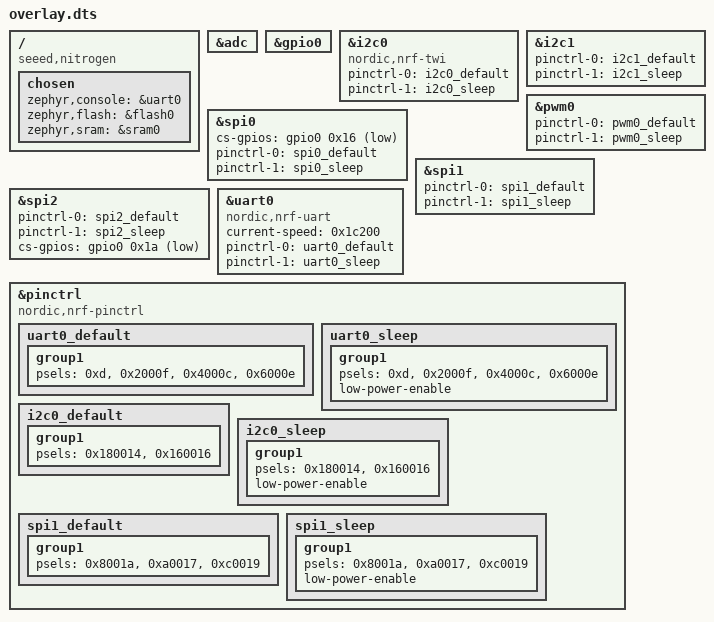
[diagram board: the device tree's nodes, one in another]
/ {
	compatible = "seeed,nitrogen";
	chosen {
		zephyr,console = &uart0;
		zephyr,flash = &flash0;
		zephyr,sram = &sram0;
	};
};
&adc{
	status = "okay";
};
&gpio0{
	status = "okay";
};
&i2c0{
	compatible = "nordic,nrf-twi";
	status = "okay";
	pinctrl-0 = < &i2c0_default >;
	pinctrl-1 = < &i2c0_sleep >;
	pinctrl-names = "default", "sleep";
};
&i2c1{
	status = "okay";
	pinctrl-0 = < &i2c1_default >;
	pinctrl-1 = < &i2c1_sleep >;
	pinctrl-names = "default", "sleep";
};
&pwm0{
	status = "okay";
	pinctrl-0 = < &pwm0_default >;
	pinctrl-1 = < &pwm0_sleep >;
	pinctrl-names = "default", "sleep";
};
&spi0{
	cs-gpios = < &gpio0 0x16 0x1 >;
	pinctrl-0 = < &spi0_default >;
	pinctrl-1 = < &spi0_sleep >;
	pinctrl-names = "default", "sleep";
};
&spi1{
	status = "okay";
	pinctrl-0 = < &spi1_default >;
	pinctrl-1 = < &spi1_sleep >;
	pinctrl-names = "default", "sleep";
};
&spi2{
	status = "okay";
	pinctrl-0 = < &spi2_default >;
	pinctrl-1 = < &spi2_sleep >;
	pinctrl-names = "default", "sleep";
	cs-gpios = < &gpio0 0x1a 0x1 >;
};
&uart0{
	compatible = "nordic,nrf-uart";
	status = "okay";
	current-speed = < 0x1c200 >;
	pinctrl-0 = < &uart0_default >;
	pinctrl-1 = < &uart0_sleep >;
	pinctrl-names = "default", "sleep";
};
&pinctrl{
	compatible = "nordic,nrf-pinctrl";
	uart0_default: uart0_default {
		group1 {
			psels = < 0xd >, < 0x2000f >, < 0x4000c >, < 0x6000e >;
		};
	};
	uart0_sleep: uart0_sleep {
		group1 {
			psels = < 0xd >, < 0x2000f >, < 0x4000c >, < 0x6000e >;
			low-power-enable;
		};
	};
	i2c0_default: i2c0_default {
		group1 {
			psels = < 0x180014 >, < 0x160016 >;
		};
	};
	i2c0_sleep: i2c0_sleep {
		group1 {
			psels = < 0x180014 >, < 0x160016 >;
			low-power-enable;
		};
	};
	spi1_default: spi1_default {
		group1 {
			psels = < 0x8001a >, < 0xa0017 >, < 0xc0019 >;
		};
	};
	spi1_sleep: spi1_sleep {
		group1 {
			psels = < 0x8001a >, < 0xa0017 >, < 0xc0019 >;
			low-power-enable;
		};
	};
};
